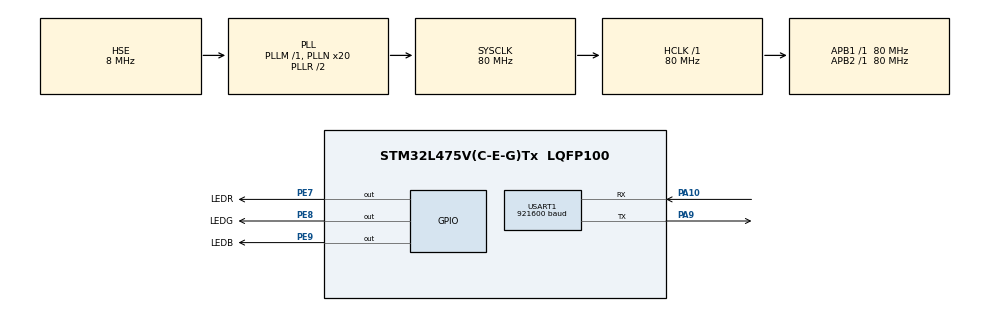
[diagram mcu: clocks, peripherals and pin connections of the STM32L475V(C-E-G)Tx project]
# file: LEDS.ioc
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Mcu.Family=STM32L4
Mcu.Name=STM32L475V(C-E-G)Tx
Mcu.Package=LQFP100
NVIC.PriorityGroup=NVIC_PRIORITYGROUP_4
PA10.Mode=Asynchronous
PA10.Signal=USART1_RX
PA13\ (JTMS-SWDIO).Mode=Serial_Wire
PA13\ (JTMS-SWDIO).Signal=SYS_JTMS-SWDIO
PA14\ (JTCK-SWCLK).Mode=Serial_Wire
PA14\ (JTCK-SWCLK).Signal=SYS_JTCK-SWCLK
PA9.Mode=Asynchronous
PA9.Signal=USART1_TX
PE7.GPIO_Label=LEDR
PE7.GPIO_ModeDefaultOutputPP=GPIO_MODE_OUTPUT_PP
PE7.GPIO_PuPd=GPIO_PULLDOWN
PE7.GPIO_Speed=GPIO_SPEED_FREQ_MEDIUM
PE7.PinState=GPIO_PIN_SET
PE7.Signal=GPIO_Output
PE8.GPIO_Label=LEDG
PE8.GPIO_ModeDefaultOutputPP=GPIO_MODE_OUTPUT_PP
PE8.GPIO_PuPd=GPIO_PULLDOWN
PE8.GPIO_Speed=GPIO_SPEED_FREQ_MEDIUM
PE8.PinState=GPIO_PIN_SET
PE8.Signal=GPIO_Output
PE9.GPIO_Label=LEDB
PE9.GPIO_ModeDefaultOutputPP=GPIO_MODE_OUTPUT_PP
PE9.GPIO_PuPd=GPIO_PULLDOWN
PE9.GPIO_Speed=GPIO_SPEED_FREQ_MEDIUM
PE9.PinState=GPIO_PIN_SET
PE9.Signal=GPIO_Output
PH0-OSC_IN\ (PH0).Mode=HSE-External-Oscillator
PH0-OSC_IN\ (PH0).Signal=RCC_OSC_IN
PH1-OSC_OUT\ (PH1).Mode=HSE-External-Oscillator
PH1-OSC_OUT\ (PH1).Signal=RCC_OSC_OUT
ProjectManager.HeapSize=0x200
ProjectManager.StackSize=0x1000
ProjectManager.TargetToolchain=MDK-ARM V5.32
RCC.ADCFreq_Value=64000000
RCC.AHBFreq_Value=80000000
RCC.APB1Freq_Value=80000000
RCC.APB1TimFreq_Value=80000000
RCC.APB2Freq_Value=80000000
RCC.APB2TimFreq_Value=80000000
RCC.CK48CLockSelection=RCC_USBCLKSOURCE_MSI
RCC.CortexFreq_Value=80000000
RCC.EnbaleCSS=true
RCC.HCLKFreq_Value=80000000
RCC.HSE_VALUE=8000000
RCC.HSI_VALUE=16000000
RCC.LSE_VALUE=32768
RCC.MSIClockRange=RCC_MSIRANGE_11
RCC.MSI_VALUE=48000000
RCC.PLLN=20
RCC.PLLSAI1N=16
RCC.PLLSourceVirtual=RCC_PLLSOURCE_HSE
RCC.SYSCLKFreq_VALUE=80000000
RCC.SYSCLKSource=RCC_SYSCLKSOURCE_PLLCLK
RCC.USBFreq_Value=48000000
RCC.VCOOutputFreq_Value=160000000
USART1.BaudRate=921600
USART1.VirtualMode-Asynchronous=VM_ASYNC
VP_CRC_VS_CRC.Mode=CRC_Activate
VP_RNG_VS_RNG.Mode=RNG_Activate
board=custom

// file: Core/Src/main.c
/* USER CODE BEGIN Header */
/**
  ******************************************************************************
  * @file           : main.c
  * @brief          : Main program body
  ******************************************************************************
  * @attention
  *
  * <h2><center>&copy; Copyright (c) 2021 STMicroelectronics.
  * All rights reserved.</center></h2>
  *
  * This software component is licensed by ST under BSD 3-Clause license,
  * the "License"; You may not use this file except in compliance with the
  * License. You may obtain a copy of the License at:
  *                        opensource.org/licenses/BSD-3-Clause
  *
  ******************************************************************************
  */
/* USER CODE END Header */
#include "main.h"
#include "crc.h"
#include "rng.h"
#include "usart.h"
#include "gpio.h"

void SystemClock_Config(void);

int main(void)
{

  /* MCU Configuration--------------------------------------------------------*/

  /* Reset of all peripherals, Initializes the Flash interface and the Systick. */
  HAL_Init();

  /* Configure the system clock */
  SystemClock_Config();

  /* Initialize all configured peripherals */
  MX_GPIO_Init();
  MX_USART1_UART_Init();
  MX_CRC_Init();
  MX_RNG_Init();

  /* Infinite loop */
  while (1)
  {

    /* USER CODE BEGIN 3 */
    HAL_GPIO_TogglePin(LEDR_GPIO_Port,LEDR_Pin);

  }
  /* USER CODE END 3 */
}

void SystemClock_Config(void)
{
  RCC_OscInitTypeDef RCC_OscInitStruct = {0};
  RCC_ClkInitTypeDef RCC_ClkInitStruct = {0};

  /** Configure the main internal regulator output voltage
  */
  if (HAL_PWREx_ControlVoltageScaling(PWR_REGULATOR_VOLTAGE_SCALE1) != HAL_OK)
  {
    Error_Handler();
  }
  /** Initializes the RCC Oscillators according to the specified parameters
  * in the RCC_OscInitTypeDef structure.
  */
  RCC_OscInitStruct.OscillatorType = RCC_OSCILLATORTYPE_HSE|RCC_OSCILLATORTYPE_MSI;
  RCC_OscInitStruct.HSEState = RCC_HSE_ON;
  RCC_OscInitStruct.MSIState = RCC_MSI_ON;
  RCC_OscInitStruct.MSICalibrationValue = 0;
  RCC_OscInitStruct.MSIClockRange = RCC_MSIRANGE_11;
  RCC_OscInitStruct.PLL.PLLState = RCC_PLL_ON;
  RCC_OscInitStruct.PLL.PLLSource = RCC_PLLSOURCE_HSE;
  RCC_OscInitStruct.PLL.PLLM = 1;
  RCC_OscInitStruct.PLL.PLLN = 20;
  RCC_OscInitStruct.PLL.PLLP = RCC_PLLP_DIV7;
  RCC_OscInitStruct.PLL.PLLQ = RCC_PLLQ_DIV2;
  RCC_OscInitStruct.PLL.PLLR = RCC_PLLR_DIV2;
  if (HAL_RCC_OscConfig(&RCC_OscInitStruct) != HAL_OK)
  {
    Error_Handler();
  }
  /** Initializes the CPU, AHB and APB buses clocks
  */
  RCC_ClkInitStruct.ClockType = RCC_CLOCKTYPE_HCLK|RCC_CLOCKTYPE_SYSCLK
                              |RCC_CLOCKTYPE_PCLK1|RCC_CLOCKTYPE_PCLK2;
  RCC_ClkInitStruct.SYSCLKSource = RCC_SYSCLKSOURCE_PLLCLK;
  RCC_ClkInitStruct.AHBCLKDivider = RCC_SYSCLK_DIV1;
  RCC_ClkInitStruct.APB1CLKDivider = RCC_HCLK_DIV1;
  RCC_ClkInitStruct.APB2CLKDivider = RCC_HCLK_DIV1;

  if (HAL_RCC_ClockConfig(&RCC_ClkInitStruct, FLASH_LATENCY_4) != HAL_OK)
  {
    Error_Handler();
  }
  /** Enables the Clock Security System
  */
  HAL_RCC_EnableCSS();
}

void Error_Handler(void)
{
  __disable_irq();
  while (1)
  {
  }
}

/************************ (C) COPYRIGHT STMicroelectronics *****END OF FILE****/
